AUTOSAR XML (schema 00050)
package /FCADT/ComponentTypes
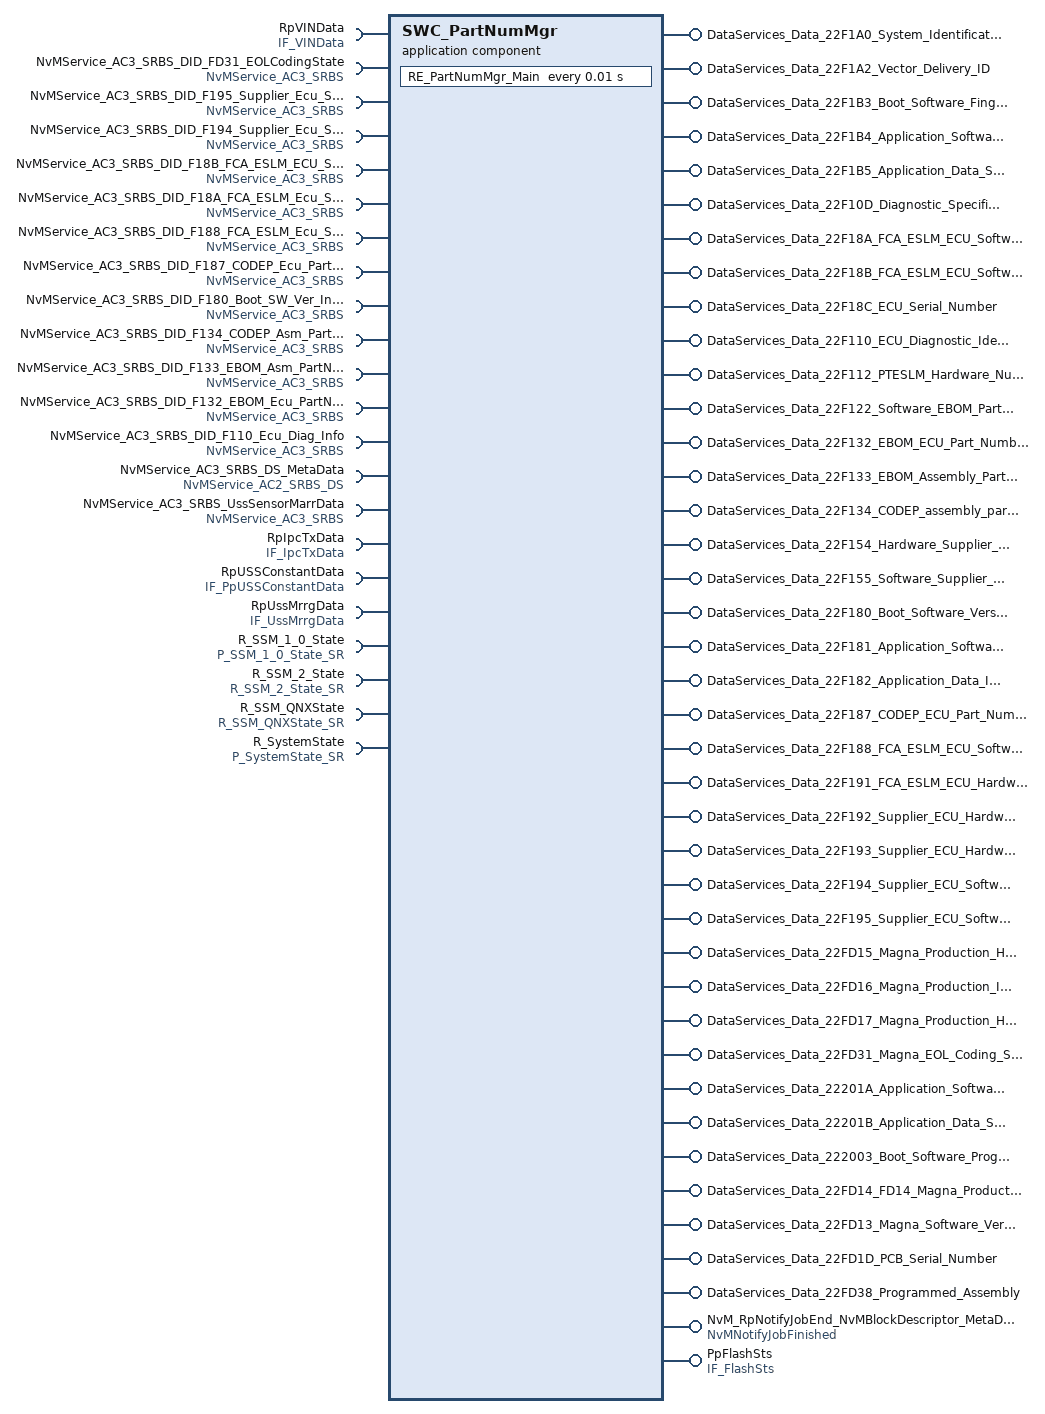
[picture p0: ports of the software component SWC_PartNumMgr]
  application sw component type SWC_PartNumMgr
    require port RpVINData: required-interface=IF_VINData
      required-com-specs:
        data-element=VINLockStatus, init-value=constant-reference=init_VINLockStatus
        data-element=VINOdoCounter, init-value=constant-reference=init_VINOdoCounter
        data-element=VINCurrentData, init-value=constant-reference=init_VINCurrentData
        data-element=VINOriginalData, init-value=constant-reference=init_VINOriginalData
    38 x provide port:
      DataServices_Data_22F1A0_System_Identification_Data: server-com-spec{operation=ReadData, queue-length=1}, provided-interface=DataServices_Data_22F1A0_System_Identification_Data
      DataServices_Data_22F1A2_Vector_Delivery_ID: server-com-spec{operation=ReadData, queue-length=1}, provided-interface=DataServices_Data_22F1A2_Vector_Delivery_ID
      DataServices_Data_22F1B3_Boot_Software_Fingerprint_Reading_Information: server-com-spec{operation=ReadData, queue-length=1}, provided-interface=DataServices_Data_22F1B3_Boot_Software_Fingerprint_Reading_Information
      DataServices_Data_22F1B4_Application_Software_Fingerprint_Reading_Information: server-com-spec{operation=ReadData, queue-length=1}, provided-interface=DataServices_Data_22F1B4_Application_Software_Fingerprint_Reading_Information
      DataServices_Data_22F1B5_Application_Data_Software_Fingerprint_Reading_Information: server-com-spec{operation=ReadData, queue-length=1}, provided-interface=DataServices_Data_22F1B5_Application_Data_Software_Fingerprint_Reading_Information
      DataServices_Data_22F10D_Diagnostic_Specification_Information: server-com-spec{operation=ReadData, queue-length=1}, provided-interface=DataServices_Data_22F10D_Diagnostic_Specification_Information
      DataServices_Data_22F18A_FCA_ESLM_ECU_Software_Calibration_Number: server-com-spec{operation=ReadData, queue-length=1}, provided-interface=DataServices_Data_22F18A_FCA_ESLM_ECU_Software_Calibration_Number
      DataServices_Data_22F18B_FCA_ESLM_ECU_Software_Application_Number: server-com-spec{operation=ReadData, queue-length=1}, provided-interface=DataServices_Data_22F18B_FCA_ESLM_ECU_Software_Application_Number
      DataServices_Data_22F18C_ECU_Serial_Number: server-com-spec{operation=ReadData, queue-length=1}, provided-interface=DataServices_Data_22F18C_ECU_Serial_Number
      DataServices_Data_22F110_ECU_Diagnostic_Identification: server-com-spec{operation=ReadData, queue-length=1}, provided-interface=DataServices_Data_22F110_ECU_Diagnostic_Identification
      DataServices_Data_22F112_PTESLM_Hardware_Number: server-com-spec{operation=ReadData, queue-length=1}, provided-interface=DataServices_Data_22F112_PTESLM_Hardware_Number
      DataServices_Data_22F122_Software_EBOM_Part_Number: server-com-spec{operation=ReadData, queue-length=1}, provided-interface=DataServices_Data_22F122_Software_EBOM_Part_Number
      DataServices_Data_22F132_EBOM_ECU_Part_Number: server-com-spec{operation=ReadData, queue-length=1}, provided-interface=DataServices_Data_22F132_EBOM_ECU_Part_Number
      DataServices_Data_22F133_EBOM_Assembly_Part_Number: server-com-spec{operation=ReadData, queue-length=1}, provided-interface=DataServices_Data_22F133_EBOM_Assembly_Part_Number
      DataServices_Data_22F134_CODEP_assembly_part_number: server-com-spec{operation=ReadData, queue-length=1}, provided-interface=DataServices_Data_22F134_CODEP_assembly_part_number
      DataServices_Data_22F154_Hardware_Supplier_Identification: server-com-spec{operation=ReadData, queue-length=1}, provided-interface=DataServices_Data_22F154_Hardware_Supplier_Identification
      DataServices_Data_22F155_Software_Supplier_Identification: server-com-spec{operation=ReadData, queue-length=1}, provided-interface=DataServices_Data_22F155_Software_Supplier_Identification
      DataServices_Data_22F180_Boot_Software_Version_Information: server-com-spec{operation=ReadData, queue-length=1}, provided-interface=DataServices_Data_22F180_Boot_Software_Version_Information
      DataServices_Data_22F181_Application_Software_Identification: server-com-spec{operation=ReadData, queue-length=1}, provided-interface=DataServices_Data_22F181_Application_Software_Identification
      DataServices_Data_22F182_Application_Data_Identification: server-com-spec{operation=ReadData, queue-length=1}, provided-interface=DataServices_Data_22F182_Application_Data_Identification
      DataServices_Data_22F187_CODEP_ECU_Part_Number: server-com-spec{operation=ReadData, queue-length=1}, provided-interface=DataServices_Data_22F187_CODEP_ECU_Part_Number
      DataServices_Data_22F188_FCA_ESLM_ECU_Software_Number: server-com-spec{operation=ReadData, queue-length=1}, provided-interface=DataServices_Data_22F188_FCA_ESLM_ECU_Software_Number
      DataServices_Data_22F191_FCA_ESLM_ECU_Hardware_Number: server-com-spec{operation=ReadData, queue-length=1}, provided-interface=DataServices_Data_22F191_FCA_ESLM_ECU_Hardware_Number
      DataServices_Data_22F192_Supplier_ECU_Hardware_Part_Number: server-com-spec{operation=ReadData, queue-length=1}, provided-interface=DataServices_Data_22F192_Supplier_ECU_Hardware_Part_Number
      DataServices_Data_22F193_Supplier_ECU_Hardware_Version_Number: server-com-spec{operation=ReadData, queue-length=1}, provided-interface=DataServices_Data_22F193_Supplier_ECU_Hardware_Version_Number
      DataServices_Data_22F194_Supplier_ECU_Software_Part_Number: server-com-spec{operation=ReadData, queue-length=1}, provided-interface=DataServices_Data_22F194_Supplier_ECU_Software_Part_Number
      DataServices_Data_22F195_Supplier_ECU_Software_Version_Number: server-com-spec{operation=ReadData, queue-length=1}, provided-interface=DataServices_Data_22F195_Supplier_ECU_Software_Version_Number
      DataServices_Data_22FD15_Magna_Production_HW_Number_Read: server-com-spec{operation=ReadData, queue-length=1}, provided-interface=DataServices_Data_22FD15_Magna_Production_HW_Number_Read
      DataServices_Data_22FD16_Magna_Production_ICT_Data_Read: server-com-spec{operation=ReadData, queue-length=1}, provided-interface=DataServices_Data_22FD16_Magna_Production_ICT_Data_Read
      DataServices_Data_22FD17_Magna_Production_HW_Version_information_Read: server-com-spec{operation=ReadData, queue-length=1}, provided-interface=DataServices_Data_22FD17_Magna_Production_HW_Version_information_Read
      DataServices_Data_22FD31_Magna_EOL_Coding_State_Read: provided-com-specs=[{operation=ReadData, queue-length=1}, {operation=WriteData, queue-length=1}], provided-interface=DataServices_Data_22FD31_Magna_EOL_Coding_State_Read
      DataServices_Data_22201A_Application_Software_Programming_Attempt_Counter: server-com-spec{operation=ReadData, queue-length=1}, provided-interface=DataServices_Data_22201A_Application_Software_Programming_Attempt_Counter
      DataServices_Data_22201B_Application_Data_Software_Programming_Attempt_Counter: server-com-spec{operation=ReadData, queue-length=1}, provided-interface=DataServices_Data_22201B_Application_Data_Software_Programming_Attempt_Counter
      DataServices_Data_222003_Boot_Software_Programming_Attempt_Counter: server-com-spec{operation=ReadData, queue-length=1}, provided-interface=DataServices_Data_222003_Boot_Software_Programming_Attempt_Counter
      DataServices_Data_22FD14_FD14_Magna_Production_Date_Read: server-com-spec{operation=ReadData, queue-length=1}, provided-interface=DataServices_Data_22FD14_FD14_Magna_Production_Date_Read
      DataServices_Data_22FD13_Magna_Software_Version: server-com-spec{operation=ReadData, queue-length=1}, provided-interface=DataServices_Data_22FD13_Magna_Software_Version
      DataServices_Data_22FD1D_PCB_Serial_Number: server-com-spec{operation=ReadData, queue-length=1}, provided-interface=DataServices_Data_22FD1D_PCB_Serial_Number
      DataServices_Data_22FD38_Programmed_Assembly: server-com-spec{operation=ReadData, queue-length=1}, provided-interface=DataServices_Data_22FD38_Programmed_Assembly
    13 x require port:
      NvMService_AC3_SRBS_DID_FD31_EOLCodingState: required-com-specs=[WriteBlock, SetRamBlockStatus, ReadBlock, InvalidateNvBlock, GetErrorStatus, EraseBlock], required-interface=NvMService_AC3_SRBS
      NvMService_AC3_SRBS_DID_F195_Supplier_Ecu_SW_VerNum: required-com-specs=[WriteBlock, SetRamBlockStatus, ReadBlock, InvalidateNvBlock, GetErrorStatus, EraseBlock], required-interface=NvMService_AC3_SRBS
      NvMService_AC3_SRBS_DID_F194_Supplier_Ecu_SW_PartNum: required-com-specs=[WriteBlock, SetRamBlockStatus, ReadBlock, InvalidateNvBlock, GetErrorStatus, EraseBlock], required-interface=NvMService_AC3_SRBS
      NvMService_AC3_SRBS_DID_F18B_FCA_ESLM_ECU_SW_App_Num: required-com-specs=[WriteBlock, SetRamBlockStatus, ReadBlock, InvalidateNvBlock, GetErrorStatus, EraseBlock], required-interface=NvMService_AC3_SRBS
      NvMService_AC3_SRBS_DID_F18A_FCA_ESLM_Ecu_SW_Cal_Num: required-com-specs=[WriteBlock, SetRamBlockStatus, ReadBlock, InvalidateNvBlock, GetErrorStatus, EraseBlock], required-interface=NvMService_AC3_SRBS
      NvMService_AC3_SRBS_DID_F188_FCA_ESLM_Ecu_SW_Num: required-com-specs=[WriteBlock, SetRamBlockStatus, ReadBlock, InvalidateNvBlock, GetErrorStatus, EraseBlock], required-interface=NvMService_AC3_SRBS
      NvMService_AC3_SRBS_DID_F187_CODEP_Ecu_PartNum: required-com-specs=[WriteBlock, SetRamBlockStatus, ReadBlock, InvalidateNvBlock, GetErrorStatus, EraseBlock], required-interface=NvMService_AC3_SRBS
      NvMService_AC3_SRBS_DID_F180_Boot_SW_Ver_Info: required-com-specs=[WriteBlock, SetRamBlockStatus, ReadBlock, InvalidateNvBlock, GetErrorStatus, EraseBlock], required-interface=NvMService_AC3_SRBS
      NvMService_AC3_SRBS_DID_F134_CODEP_Asm_PartNum: required-com-specs=[WriteBlock, SetRamBlockStatus, ReadBlock, InvalidateNvBlock, GetErrorStatus, EraseBlock], required-interface=NvMService_AC3_SRBS
      NvMService_AC3_SRBS_DID_F133_EBOM_Asm_PartNum: required-com-specs=[WriteBlock, SetRamBlockStatus, ReadBlock, InvalidateNvBlock, GetErrorStatus, EraseBlock], required-interface=NvMService_AC3_SRBS
      NvMService_AC3_SRBS_DID_F132_EBOM_Ecu_PartNum: required-com-specs=[WriteBlock, SetRamBlockStatus, ReadBlock, InvalidateNvBlock, GetErrorStatus, EraseBlock], required-interface=NvMService_AC3_SRBS
      NvMService_AC3_SRBS_DID_F110_Ecu_Diag_Info: required-com-specs=[WriteBlock, SetRamBlockStatus, ReadBlock, InvalidateNvBlock, GetErrorStatus, EraseBlock], required-interface=NvMService_AC3_SRBS
      NvMService_AC3_SRBS_DS_MetaData: required-com-specs=[WriteBlock, SetRamBlockStatus, SetDataIndex, ReadBlock, GetErrorStatus, GetDataIndex], required-interface=NvMService_AC2_SRBS_DS
    provide port NvM_RpNotifyJobEnd_NvMBlockDescriptor_MetaData: server-com-spec{operation=JobFinished, queue-length=1}, provided-interface=NvMNotifyJobFinished
    7 x require port:
      NvMService_AC3_SRBS_UssSensorMarrData: required-com-specs=[WriteBlock, SetRamBlockStatus, ReadBlock, InvalidateNvBlock, GetErrorStatus, EraseBlock], required-interface=NvMService_AC3_SRBS
      RpIpcTxData: client-com-spec=IPC_Write_v, required-interface=IF_IpcTxData
      RpUSSConstantData: nonqueued-receiver-com-spec{data-element=US_S_USSConstantData_t, filter=data-filter-type=ALWAYS}, required-interface=IF_PpUSSConstantData
      RpUssMrrgData: nonqueued-receiver-com-spec{data-element=US_S_MarriageSensorIDs_t, filter=data-filter-type=ALWAYS, init-value=fields=[bValid:0, uMarriageStatus:0, uSavedSensorIDs:12 x 0]}, required-interface=IF_UssMrrgData
      R_SSM_1_0_State: nonqueued-receiver-com-spec{data-element=State_1_0, init-value=fields=[CoreStatus:0, LocalAppStatus:20 x 0]}, required-interface=P_SSM_1_0_State_SR
      R_SSM_2_State: required-interface=R_SSM_2_State_SR
        required-com-specs:
          data-element=State_2_0, init-value=fields=[CoreStatus:0, LocalAppStatus:20 x 0]
          data-element=State_2_1, filter=data-filter-type=ALWAYS, init-value=fields=[CoreStatus:0, LocalAppStatus:20 x 0]
      R_SSM_QNXState: nonqueued-receiver-com-spec{data-element=State_QNX, init-value=fields=[CoreStatus:0, LocalAppStatus:20 x 0]}, required-interface=R_SSM_QNXState_SR
    provide port PpFlashSts: nonqueued-sender-com-spec{data-element=v_FlashSts_u16, init-value=0}, provided-interface=IF_FlashSts
    require port R_SystemState: nonqueued-receiver-com-spec=data-element=SystemState, required-interface=P_SystemState_SR
    behavior SWC_PartNumMgr_InternalBehavior: handle-termination-and-restart=NO-SUPPORT
      ar-typed-per-instance-memorys:
        13 x data, all with sw-calibration-access=READ-ONLY:
          DID_FD31_EOLCodingState_MirrorBlock: type=Dcm_Data4ByteType
          DID_F195_Supplier_Ecu_SW_VerNum_MirrorBlock: type=Dcm_Data2ByteType
          DID_F194_Supplier_Ecu_SW_PartNum_MirrorBlock: type=Dcm_Data11ByteType
          DID_F18B_FCA_ESLM_ECU_SW_App_Num_MirrorBlock: type=Dcm_Data10ByteType
          DID_F18A_FCA_ESLM_Ecu_SW_Cal_Num_MirrorBlock: type=Dcm_Data10ByteType
          DID_F188_FCA_ESLM_Ecu_SW_Num_MirrorBlock: type=Dcm_Data11ByteType
          DID_F187_CODEP_Ecu_PartNum_MirrorBlock: type=Dcm_Data11ByteType
          DID_F180_Boot_SW_Ver_Info_MirrorBlock: type=Dcm_Data13ByteType
          DID_F134_CODEP_Asm_PartNum_MirrorBlock: type=Dcm_Data11ByteType
          DID_F133_EBOM_Asm_PartNum_MirrorBlock: type=Dcm_Data10ByteType
          DID_F132_EBOM_Ecu_PartNum_MirrorBlock: type=Dcm_Data10ByteType
          DID_F110_Ecu_Diag_Info_MirrorBlock: type=DID_F110_Pin_Arr
          UssSensorMarrData_MirrorBlock: type=US_S_MarriageSensorIDs_t
      init event InitEvent: start-on-event=RE_PartNumMgr_Init
      timing event TMT_RE_PartNumMgr_Main: start-on-event=RE_PartNumMgr_Main, period=0.01
      40 x operation invoked event:
        OIT_DataServices_Data_222003_Boot_Software_Programming_Attempt_Counter_ReadData_DataServices_Data_222003_Boot_Software_P7618A5A4: start-on-event=DataServices_Data_222003_Boot_Software_Programming_Attempt_Counter_ReadData, operation=DataServices_Data_222003_Boot_Software_Programming_Attempt_Counter.ReadData
        OIT_DataServices_Data_22F180_Boot_Software_Version_Information_ReadData_DataServices_Data_22F180_Boot_Software_Version_IFD2EFA80: start-on-event=DataServices_Data_22F180_Boot_Software_Version_Information_ReadData, operation=DataServices_Data_22F180_Boot_Software_Version_Information.ReadData
        OIT_DataServices_Data_22F18A_FCA_ESLM_ECU_Software_Calibration_Number_ReadData_DataServices_Data_22F18A_FCA_ESLM_ECU_SofDF68DFA8: start-on-event=DataServices_Data_22F18A_FCA_ESLM_ECU_Software_Calibration_Number_ReadData, operation=DataServices_Data_22F18A_FCA_ESLM_ECU_Software_Calibration_Number.ReadData
        OIT_DataServices_Data_22FD16_Magna_Production_ICT_Data_Read_ReadData_DataServices_Data_22FD16_Magna_Production_ICT_Data_1B05D7E7: start-on-event=DataServices_Data_22FD16_Magna_Production_ICT_Data_Read_ReadData, operation=DataServices_Data_22FD16_Magna_Production_ICT_Data_Read.ReadData
        OIT_DataServices_Data_22F188_FCA_ESLM_ECU_Software_Number_ReadData_DataServices_Data_22F188_FCA_ESLM_ECU_Software_Number457EFB64: start-on-event=DataServices_Data_22F188_FCA_ESLM_ECU_Software_Number_ReadData, operation=DataServices_Data_22F188_FCA_ESLM_ECU_Software_Number.ReadData
        OIT_DataServices_Data_22F182_Application_Data_Identification_ReadData_DataServices_Data_22F182_Application_Data_IdentifiB7E15006: start-on-event=DataServices_Data_22F182_Application_Data_Identification_ReadData, operation=DataServices_Data_22F182_Application_Data_Identification.ReadData
        OIT_DataServices_Data_22F192_Supplier_ECU_Hardware_Part_Number_ReadData_DataServices_Data_22F192_Supplier_ECU_Hardware_P8807FD4D: start-on-event=DataServices_Data_22F192_Supplier_ECU_Hardware_Part_Number_ReadData, operation=DataServices_Data_22F192_Supplier_ECU_Hardware_Part_Number.ReadData
        OIT_DataServices_Data_22F10D_Diagnostic_Specification_Information_ReadData_DataServices_Data_22F10D_Diagnostic_Specifica91CF8A26: start-on-event=DataServices_Data_22F10D_Diagnostic_Specification_Information_ReadData, operation=DataServices_Data_22F10D_Diagnostic_Specification_Information.ReadData
        OIT_DataServices_Data_22FD17_Magna_Production_HW_Version_information_Read_ReadData_DataServices_Data_22FD17_Magna_Produc06BFFE9B: start-on-event=DataServices_Data_22FD17_Magna_Production_HW_Version_information_Read_ReadData, operation=DataServices_Data_22FD17_Magna_Production_HW_Version_information_Read.ReadData
        OIT_DataServices_Data_22F191_FCA_ESLM_ECU_Hardware_Number_ReadData_DataServices_Data_22F191_FCA_ESLM_ECU_Hardware_Number5EEDE70D: start-on-event=DataServices_Data_22F191_FCA_ESLM_ECU_Hardware_Number_ReadData, operation=DataServices_Data_22F191_FCA_ESLM_ECU_Hardware_Number.ReadData
        OIT_DataServices_Data_22F1B5_Application_Data_Software_Fingerprint_Reading_Information_ReadData_DataServices_Data_22F1B51DE0B2F4: start-on-event=DataServices_Data_22F1B5_Application_Data_Software_Fingerprint_Reading_Information_ReadData, operation=DataServices_Data_22F1B5_Application_Data_Software_Fingerprint_Reading_Information.ReadData
        OIT_DataServices_Data_22FD15_Magna_Production_HW_Number_Read_ReadData_DataServices_Data_22FD15_Magna_Production_HW_Numbe6743EEE1: start-on-event=DataServices_Data_22FD15_Magna_Production_HW_Number_Read_ReadData, operation=DataServices_Data_22FD15_Magna_Production_HW_Number_Read.ReadData
        OIT_DataServices_Data_22F154_Hardware_Supplier_Identification_ReadData_DataServices_Data_22F154_Hardware_Supplier_Identi565FF852: start-on-event=DataServices_Data_22F154_Hardware_Supplier_Identification_ReadData, operation=DataServices_Data_22F154_Hardware_Supplier_Identification.ReadData
        OIT_DataServices_Data_22F132_EBOM_ECU_Part_Number_ReadData_DataServices_Data_22F132_EBOM_ECU_Part_Number_ReadData: start-on-event=DataServices_Data_22F132_EBOM_ECU_Part_Number_ReadData, operation=DataServices_Data_22F132_EBOM_ECU_Part_Number.ReadData
        OIT_DataServices_Data_22F110_ECU_Diagnostic_Identification_ReadData_DataServices_Data_22F110_ECU_Diagnostic_IdentificatiE46CBB4A: start-on-event=DataServices_Data_22F110_ECU_Diagnostic_Identification_ReadData, operation=DataServices_Data_22F110_ECU_Diagnostic_Identification.ReadData
        OIT_DataServices_Data_22F133_EBOM_Assembly_Part_Number_ReadData_DataServices_Data_22F133_EBOM_Assembly_Part_Number_ReadData: start-on-event=DataServices_Data_22F133_EBOM_Assembly_Part_Number_ReadData, operation=DataServices_Data_22F133_EBOM_Assembly_Part_Number.ReadData
        OIT_DataServices_Data_22F134_CODEP_assembly_part_number_ReadData_DataServices_Data_22F134_CODEP_assembly_part_number_ReadData: start-on-event=DataServices_Data_22F134_CODEP_assembly_part_number_ReadData, operation=DataServices_Data_22F134_CODEP_assembly_part_number.ReadData
        OIT_DataServices_Data_22F112_PTESLM_Hardware_Number_ReadData_DataServices_Data_22F112_PTESLM_Hardware_Number_ReadData: start-on-event=DataServices_Data_22F112_PTESLM_Hardware_Number_ReadData, operation=DataServices_Data_22F112_PTESLM_Hardware_Number.ReadData
        OIT_DataServices_Data_22201A_Application_Software_Programming_Attempt_Counter_ReadData_DataServices_Data_22201A_ApplicatCDDECFD6: start-on-event=DataServices_Data_22201A_Application_Software_Programming_Attempt_Counter_ReadData, operation=DataServices_Data_22201A_Application_Software_Programming_Attempt_Counter.ReadData
        OIT_DataServices_Data_22F194_Supplier_ECU_Software_Part_Number_ReadData_DataServices_Data_22F194_Supplier_ECU_Software_PF5FA3120: start-on-event=DataServices_Data_22F194_Supplier_ECU_Software_Part_Number_ReadData, operation=DataServices_Data_22F194_Supplier_ECU_Software_Part_Number.ReadData
        OIT_DataServices_Data_22F181_Application_Software_Identification_ReadData_DataServices_Data_22F181_Application_Software_D66047AC: start-on-event=DataServices_Data_22F181_Application_Software_Identification_ReadData, operation=DataServices_Data_22F181_Application_Software_Identification.ReadData
        OIT_DataServices_Data_22F195_Supplier_ECU_Software_Version_Number_ReadData_DataServices_Data_22F195_Supplier_ECU_SoftwarD5BB4A4E: start-on-event=DataServices_Data_22F195_Supplier_ECU_Software_Version_Number_ReadData, operation=DataServices_Data_22F195_Supplier_ECU_Software_Version_Number.ReadData
        OIT_DataServices_Data_22F18C_ECU_Serial_Number_ReadData_DataServices_Data_22F18C_ECU_Serial_Number_ReadData: start-on-event=DataServices_Data_22F18C_ECU_Serial_Number_ReadData, operation=DataServices_Data_22F18C_ECU_Serial_Number.ReadData
        OIT_DataServices_Data_22F193_Supplier_ECU_Hardware_Version_Number_ReadData_DataServices_Data_22F193_Supplier_ECU_Hardwar33F2C41C: start-on-event=DataServices_Data_22F193_Supplier_ECU_Hardware_Version_Number_ReadData, operation=DataServices_Data_22F193_Supplier_ECU_Hardware_Version_Number.ReadData
        OIT_DataServices_Data_22F155_Software_Supplier_Identification_ReadData_DataServices_Data_22F155_Software_Supplier_Identi5611B37E: start-on-event=DataServices_Data_22F155_Software_Supplier_Identification_ReadData, operation=DataServices_Data_22F155_Software_Supplier_Identification.ReadData
        OIT_DataServices_Data_22F1A0_System_Identification_Data_ReadData_DataServices_Data_22F1A0_System_Identification_Data_ReadData: start-on-event=DataServices_Data_22F1A0_System_Identification_Data_ReadData, operation=DataServices_Data_22F1A0_System_Identification_Data.ReadData
        OIT_DataServices_Data_22F1B3_Boot_Software_Fingerprint_Reading_Information_ReadData_DataServices_Data_22F1B3_Boot_Softwa5F5B6A24: start-on-event=DataServices_Data_22F1B3_Boot_Software_Fingerprint_Reading_Information_ReadData, operation=DataServices_Data_22F1B3_Boot_Software_Fingerprint_Reading_Information.ReadData
        OIT_DataServices_Data_22F18B_FCA_ESLM_ECU_Software_Application_Number_ReadData_DataServices_Data_22F18B_FCA_ESLM_ECU_Sof869D5A40: start-on-event=DataServices_Data_22F18B_FCA_ESLM_ECU_Software_Application_Number_ReadData, operation=DataServices_Data_22F18B_FCA_ESLM_ECU_Software_Application_Number.ReadData
        OIT_DataServices_Data_22F187_CODEP_ECU_Part_Number_ReadData_DataServices_Data_22F187_CODEP_ECU_Part_Number_ReadData: start-on-event=DataServices_Data_22F187_CODEP_ECU_Part_Number_ReadData, operation=DataServices_Data_22F187_CODEP_ECU_Part_Number.ReadData
        OIT_DataServices_Data_22201B_Application_Data_Software_Programming_Attempt_Counter_ReadData_DataServices_Data_22201B_App20424928: start-on-event=DataServices_Data_22201B_Application_Data_Software_Programming_Attempt_Counter_ReadData, operation=DataServices_Data_22201B_Application_Data_Software_Programming_Attempt_Counter.ReadData
        OIT_DataServices_Data_22F1B4_Application_Software_Fingerprint_Reading_Information_ReadData_DataServices_Data_22F1B4_Appl1F41231D: start-on-event=DataServices_Data_22F1B4_Application_Software_Fingerprint_Reading_Information_ReadData, operation=DataServices_Data_22F1B4_Application_Software_Fingerprint_Reading_Information.ReadData
        OIT_DataServices_Data_22FD31_Magna_EOL_Coding_State_Read_WriteData_DataServices_Data_22FD31_Magna_EOL_Coding_State_Read_6E34A382: start-on-event=DataServices_Data_22FD31_Magna_EOL_Coding_State_Read_WriteData, operation=DataServices_Data_22FD31_Magna_EOL_Coding_State_Read.WriteData
        OIT_DataServices_Data_22FD31_Magna_EOL_Coding_State_Read_ReadData_DataServices_Data_22FD31_Magna_EOL_Coding_State_Read_ReadData: start-on-event=DataServices_Data_22FD31_Magna_EOL_Coding_State_Read_ReadData, operation=DataServices_Data_22FD31_Magna_EOL_Coding_State_Read.ReadData
        OIT_DataServices_Data_22F122_Software_EBOM_Part_Number_ReadData_DataServices_Data_22F122_Software_EBOM_Part_Number_ReadData: start-on-event=DataServices_Data_22F122_Software_EBOM_Part_Number_ReadData, operation=DataServices_Data_22F122_Software_EBOM_Part_Number.ReadData
        OIT_DataServices_Data_22F1A2_Vector_Delivery_ID_ReadData_DataServices_Data_22F1A2_Vector_Delivery_ID_ReadData: start-on-event=DataServices_Data_22F1A2_Vector_Delivery_ID_ReadData, operation=DataServices_Data_22F1A2_Vector_Delivery_ID.ReadData
        OIT_DataServices_Data_22FD13_Magna_Software_Version_ReadData_1_DataServices_Data_22FD13_Magna_Software_Version_ReadData: start-on-event=DataServices_Data_22FD13_Magna_Software_Version_ReadData, operation=DataServices_Data_22FD13_Magna_Software_Version.ReadData
        OIT_DataServices_Data_22FD14_FD14_Magna_Production_Date_Read_ReadData_1_DataServices_Data_22FD14_FD14_Magna_Production_DC024ADC0: start-on-event=DataServices_Data_22FD14_FD14_Magna_Production_Date_Read_ReadData, operation=DataServices_Data_22FD14_FD14_Magna_Production_Date_Read.ReadData
        OIT_DataServices_Data_22FD38_Programmed_Assembly_ReadData_1_DataServices_Data_22FD38_Programmed_Assembly_ReadData: start-on-event=DataServices_Data_22FD38_Programmed_Assembly_ReadData, operation=DataServices_Data_22FD38_Programmed_Assembly.ReadData
        OIT_DataServices_Data_22FD1D_PCB_Serial_Number_ReadData_1_DataServices_Data_22FD1D_PCB_Serial_Number_ReadData: start-on-event=DataServices_Data_22FD1D_PCB_Serial_Number_ReadData, operation=DataServices_Data_22FD1D_PCB_Serial_Number.ReadData
        OIT_RE_NvM_RpNotifyJobEnd_NvMBlockDescriptor_MetaData_JobFinished_NvM_RpNotifyJobEnd_NvMBlockDescriptor_MetaData_JobFinished: start-on-event=RE_NvM_RpNotifyJobEnd_NvMBlockDescriptor_MetaData_JobFinished, operation=NvM_RpNotifyJobEnd_NvMBlockDescriptor_MetaData.JobFinished
      per-instance-parameters:
        13 x parameter data prototype, all with sw-calibration-access=READ-WRITE:
          DID_FD31_EOLCodingState_DefaultValue: type=Dcm_Data4ByteType, init-value=[0, 0, 0, 0]
          DID_F195_Supplier_Ecu_SW_VerNum_DefaultValue: type=Dcm_Data2ByteType, init-value=[0, 0]
          DID_F194_Supplier_Ecu_SW_PartNum_DefaultValue: type=Dcm_Data11ByteType, init-value=11 x 0
          DID_F18B_FCA_ESLM_ECU_SW_App_Num_DefaultValue: type=Dcm_Data10ByteType, init-value=10 x 0
          DID_F18A_FCA_ESLM_Ecu_SW_Cal_Num_DefaultValue: type=Dcm_Data10ByteType, init-value=10 x 0
          DID_F188_FCA_ESLM_Ecu_SW_Num_DefaultValue: type=Dcm_Data11ByteType, init-value=11 x 0
          DID_F187_CODEP_Ecu_PartNum_DefaultValue: type=Dcm_Data11ByteType, init-value=11 x 0
          DID_F180_Boot_SW_Ver_Info_DefaultValue: type=Dcm_Data13ByteType, init-value=13 x 0
          DID_F134_CODEP_Asm_PartNum_DefaultValue: type=Dcm_Data11ByteType, init-value=11 x 0
          DID_F133_EBOM_Asm_PartNum_DefaultValue: type=Dcm_Data10ByteType, init-value=10 x 0
          DID_F132_EBOM_Ecu_PartNum_DefaultValue: type=Dcm_Data10ByteType, init-value=10 x 0
          DID_F110_Ecu_Diag_Info_DefaultValue: type=DID_F110_Pin_Arr, init-value=6 x 0
          UssSensorMarrData_DefaultValue: type=US_S_MarriageSensorIDs_t, init-value=fields=[bValid:0, uMarriageStatus:0, uSavedSensorIDs:12 x 0]
      port-api-options:
        enable-take-address=false, error-handling=NO-TRANSFORMER-ERROR-HANDLING, indirect-api=false, port=RpVINData
        enable-take-address=false, error-handling=NO-TRANSFORMER-ERROR-HANDLING, indirect-api=false, port=DataServices_Data_222003_Boot_Software_Programming_Attempt_Counter
        enable-take-address=false, error-handling=NO-TRANSFORMER-ERROR-HANDLING, indirect-api=false, port=DataServices_Data_22201A_Application_Software_Programming_Attempt_Counter
        enable-take-address=false, error-handling=NO-TRANSFORMER-ERROR-HANDLING, indirect-api=false, port=DataServices_Data_22201B_Application_Data_Software_Programming_Attempt_Counter
        enable-take-address=false, error-handling=NO-TRANSFORMER-ERROR-HANDLING, indirect-api=false, port=DataServices_Data_22F10D_Diagnostic_Specification_Information
        enable-take-address=false, error-handling=NO-TRANSFORMER-ERROR-HANDLING, indirect-api=false, port=DataServices_Data_22F110_ECU_Diagnostic_Identification
        enable-take-address=false, error-handling=NO-TRANSFORMER-ERROR-HANDLING, indirect-api=false, port=DataServices_Data_22F112_PTESLM_Hardware_Number
        enable-take-address=false, error-handling=NO-TRANSFORMER-ERROR-HANDLING, indirect-api=false, port=DataServices_Data_22F122_Software_EBOM_Part_Number
        enable-take-address=false, error-handling=NO-TRANSFORMER-ERROR-HANDLING, indirect-api=false, port=DataServices_Data_22F132_EBOM_ECU_Part_Number
        enable-take-address=false, error-handling=NO-TRANSFORMER-ERROR-HANDLING, indirect-api=false, port=DataServices_Data_22F133_EBOM_Assembly_Part_Number
        enable-take-address=false, error-handling=NO-TRANSFORMER-ERROR-HANDLING, indirect-api=false, port=DataServices_Data_22F134_CODEP_assembly_part_number
        enable-take-address=false, error-handling=NO-TRANSFORMER-ERROR-HANDLING, indirect-api=false, port=DataServices_Data_22F154_Hardware_Supplier_Identification
        enable-take-address=false, error-handling=NO-TRANSFORMER-ERROR-HANDLING, indirect-api=false, port=DataServices_Data_22F155_Software_Supplier_Identification
        enable-take-address=false, error-handling=NO-TRANSFORMER-ERROR-HANDLING, indirect-api=false, port=DataServices_Data_22F180_Boot_Software_Version_Information
        enable-take-address=false, error-handling=NO-TRANSFORMER-ERROR-HANDLING, indirect-api=false, port=DataServices_Data_22F181_Application_Software_Identification
        enable-take-address=false, error-handling=NO-TRANSFORMER-ERROR-HANDLING, indirect-api=false, port=DataServices_Data_22F182_Application_Data_Identification
        enable-take-address=false, error-handling=NO-TRANSFORMER-ERROR-HANDLING, indirect-api=false, port=DataServices_Data_22F187_CODEP_ECU_Part_Number
        enable-take-address=false, error-handling=NO-TRANSFORMER-ERROR-HANDLING, indirect-api=false, port=DataServices_Data_22F188_FCA_ESLM_ECU_Software_Number
        enable-take-address=false, error-handling=NO-TRANSFORMER-ERROR-HANDLING, indirect-api=false, port=DataServices_Data_22F18A_FCA_ESLM_ECU_Software_Calibration_Number
        enable-take-address=false, error-handling=NO-TRANSFORMER-ERROR-HANDLING, indirect-api=false, port=DataServices_Data_22F18B_FCA_ESLM_ECU_Software_Application_Number
        enable-take-address=false, error-handling=NO-TRANSFORMER-ERROR-HANDLING, indirect-api=false, port=DataServices_Data_22F18C_ECU_Serial_Number
        enable-take-address=false, error-handling=NO-TRANSFORMER-ERROR-HANDLING, indirect-api=false, port=DataServices_Data_22F191_FCA_ESLM_ECU_Hardware_Number
        enable-take-address=false, error-handling=NO-TRANSFORMER-ERROR-HANDLING, indirect-api=false, port=DataServices_Data_22F192_Supplier_ECU_Hardware_Part_Number
        enable-take-address=false, error-handling=NO-TRANSFORMER-ERROR-HANDLING, indirect-api=false, port=DataServices_Data_22F193_Supplier_ECU_Hardware_Version_Number
        enable-take-address=false, error-handling=NO-TRANSFORMER-ERROR-HANDLING, indirect-api=false, port=DataServices_Data_22F194_Supplier_ECU_Software_Part_Number
        enable-take-address=false, error-handling=NO-TRANSFORMER-ERROR-HANDLING, indirect-api=false, port=DataServices_Data_22F195_Supplier_ECU_Software_Version_Number
        enable-take-address=false, error-handling=NO-TRANSFORMER-ERROR-HANDLING, indirect-api=false, port=DataServices_Data_22F1A0_System_Identification_Data
        enable-take-address=false, error-handling=NO-TRANSFORMER-ERROR-HANDLING, indirect-api=false, port=DataServices_Data_22F1A2_Vector_Delivery_ID
        enable-take-address=false, error-handling=NO-TRANSFORMER-ERROR-HANDLING, indirect-api=false, port=DataServices_Data_22F1B3_Boot_Software_Fingerprint_Reading_Information
        enable-take-address=false, error-handling=NO-TRANSFORMER-ERROR-HANDLING, indirect-api=false, port=DataServices_Data_22F1B4_Application_Software_Fingerprint_Reading_Information
        enable-take-address=false, error-handling=NO-TRANSFORMER-ERROR-HANDLING, indirect-api=false, port=DataServices_Data_22F1B5_Application_Data_Software_Fingerprint_Reading_Information
        enable-take-address=false, error-handling=NO-TRANSFORMER-ERROR-HANDLING, indirect-api=false, port=DataServices_Data_22FD15_Magna_Production_HW_Number_Read
        enable-take-address=false, error-handling=NO-TRANSFORMER-ERROR-HANDLING, indirect-api=false, port=DataServices_Data_22FD16_Magna_Production_ICT_Data_Read
        enable-take-address=false, error-handling=NO-TRANSFORMER-ERROR-HANDLING, indirect-api=false, port=DataServices_Data_22FD17_Magna_Production_HW_Version_information_Read
        enable-take-address=false, error-handling=NO-TRANSFORMER-ERROR-HANDLING, indirect-api=false, port=DataServices_Data_22FD31_Magna_EOL_Coding_State_Read
      42 x runnable:
        RE_PartNumMgr_Init
          sync call SC_NvMService_AC3_SRBS_DS_MetaData_ReadBlock: operation=NvMService_AC3_SRBS_DS_MetaData.ReadBlock
          sync call SC_NvMService_AC3_SRBS_DS_MetaData_SetDataIndex: operation=NvMService_AC3_SRBS_DS_MetaData.SetDataIndex
        RE_PartNumMgr_Main
          data-receive-point-by-arguments:
            11 x access:
              REC_RpVINData_VINCurrentData: accessed-variable=RpVINData.VINCurrentData
              REC_RpVINData_VINLockStatus: accessed-variable=RpVINData.VINLockStatus
              REC_RpVINData_VINOdoCounter: accessed-variable=RpVINData.VINOdoCounter
              REC_RpVINData_VINOriginalData: accessed-variable=RpVINData.VINOriginalData
              REC_RpUSSConstantData_US_S_USSConstantData_t: accessed-variable=RpUSSConstantData.US_S_USSConstantData_t
              REC_RpUssMrrgData_US_S_MarriageSensorIDs_t: accessed-variable=RpUssMrrgData.US_S_MarriageSensorIDs_t
              REC_R_SSM_1_0_State_State_1_0: accessed-variable=R_SSM_1_0_State.State_1_0
              REC_R_SSM_2_State_State_2_0: accessed-variable=R_SSM_2_State.State_2_0
              REC_R_SSM_2_State_State_2_1: accessed-variable=R_SSM_2_State.State_2_1
              REC_R_SSM_QNXState_State_QNX: accessed-variable=R_SSM_QNXState.State_QNX
              REC_R_SystemState_SystemState: accessed-variable=R_SystemState.SystemState
          data-send-points:
            access SEND_PpFlashSts_v_FlashSts_u16: accessed-variable=PpFlashSts.v_FlashSts_u16
          4 x sync call:
            SC_NvMService_AC3_SRBS_DID_FD31_EOLCodingState_SetRamBlockStatus: operation=NvMService_AC3_SRBS_DID_FD31_EOLCodingState.SetRamBlockStatus
            SC_NvMService_AC3_SRBS_UssSensorMarrData_SetRamBlockStatus: operation=NvMService_AC3_SRBS_UssSensorMarrData.SetRamBlockStatus
            SC_NvMService_AC3_SRBS_UssSensorMarrData_WriteBlock: operation=NvMService_AC3_SRBS_UssSensorMarrData.WriteBlock
            SC_RpIpcTxData_IPC_Write_v: operation=RpIpcTxData.IPC_Write_v
        DataServices_Data_222003_Boot_Software_Programming_Attempt_Counter_ReadData
        DataServices_Data_22F180_Boot_Software_Version_Information_ReadData
        DataServices_Data_22F18A_FCA_ESLM_ECU_Software_Calibration_Number_ReadData
        DataServices_Data_22FD16_Magna_Production_ICT_Data_Read_ReadData
        DataServices_Data_22F188_FCA_ESLM_ECU_Software_Number_ReadData
        DataServices_Data_22F182_Application_Data_Identification_ReadData
        DataServices_Data_22F192_Supplier_ECU_Hardware_Part_Number_ReadData
        DataServices_Data_22F10D_Diagnostic_Specification_Information_ReadData
        DataServices_Data_22FD17_Magna_Production_HW_Version_information_Read_ReadData
        DataServices_Data_22F191_FCA_ESLM_ECU_Hardware_Number_ReadData
        DataServices_Data_22F1B5_Application_Data_Software_Fingerprint_Reading_Information_ReadData
        DataServices_Data_22FD15_Magna_Production_HW_Number_Read_ReadData
        DataServices_Data_22F154_Hardware_Supplier_Identification_ReadData
        DataServices_Data_22F132_EBOM_ECU_Part_Number_ReadData
        DataServices_Data_22F110_ECU_Diagnostic_Identification_ReadData
        DataServices_Data_22F133_EBOM_Assembly_Part_Number_ReadData
        DataServices_Data_22F134_CODEP_assembly_part_number_ReadData
        DataServices_Data_22F112_PTESLM_Hardware_Number_ReadData
        DataServices_Data_22201A_Application_Software_Programming_Attempt_Counter_ReadData
        DataServices_Data_22F194_Supplier_ECU_Software_Part_Number_ReadData
        DataServices_Data_22F181_Application_Software_Identification_ReadData
        DataServices_Data_22F195_Supplier_ECU_Software_Version_Number_ReadData
        DataServices_Data_22F18C_ECU_Serial_Number_ReadData
        DataServices_Data_22F193_Supplier_ECU_Hardware_Version_Number_ReadData
        DataServices_Data_22F155_Software_Supplier_Identification_ReadData
        DataServices_Data_22F1A0_System_Identification_Data_ReadData
        DataServices_Data_22F1B3_Boot_Software_Fingerprint_Reading_Information_ReadData
        DataServices_Data_22F18B_FCA_ESLM_ECU_Software_Application_Number_ReadData
        DataServices_Data_22F187_CODEP_ECU_Part_Number_ReadData
        DataServices_Data_22201B_Application_Data_Software_Programming_Attempt_Counter_ReadData
        DataServices_Data_22F1B4_Application_Software_Fingerprint_Reading_Information_ReadData
        DataServices_Data_22FD31_Magna_EOL_Coding_State_Read_WriteData
        DataServices_Data_22FD31_Magna_EOL_Coding_State_Read_ReadData
        DataServices_Data_22F122_Software_EBOM_Part_Number_ReadData
        DataServices_Data_22F1A2_Vector_Delivery_ID_ReadData
        DataServices_Data_22FD13_Magna_Software_Version_ReadData
        DataServices_Data_22FD14_FD14_Magna_Production_Date_Read_ReadData
        DataServices_Data_22FD38_Programmed_Assembly_ReadData
        DataServices_Data_22FD1D_PCB_Serial_Number_ReadData
        RE_NvM_RpNotifyJobEnd_NvMBlockDescriptor_MetaData_JobFinished
      13 x swc service dependency, all with category=SERVICE:
        DID_FD31_EOLCodingState: assigned-ports=role-based-port-assignment={port-prototype=NvMService_AC3_SRBS_DID_FD31_EOLCodingState, role=NvMService_AC3_SRBS}
          assigned-datas:
            role=ramBlock, used-data-element=DID_FD31_EOLCodingState_MirrorBlock
            role=defaultValue, used-parameter-element=DID_FD31_EOLCodingState_DefaultValue
          service-needs:
            nv block needs DID_FD31_EOLCodingState: n-data-sets=1, ram-block-status-control=API, reliability=NO-PROTECTION, restore-at-start=true, store-at-shutdown=true
        DID_F195_Supplier_Ecu_SW_VerNum: assigned-ports=role-based-port-assignment={port-prototype=NvMService_AC3_SRBS_DID_F195_Supplier_Ecu_SW_VerNum, role=NvMService_AC3_SRBS}
          assigned-datas:
            role=ramBlock, used-data-element=DID_F195_Supplier_Ecu_SW_VerNum_MirrorBlock
            role=defaultValue, used-parameter-element=DID_F195_Supplier_Ecu_SW_VerNum_DefaultValue
          service-needs:
            nv block needs DID_F195_Supplier_Ecu_SW_VerNum: n-data-sets=1, ram-block-status-control=API, reliability=NO-PROTECTION, restore-at-start=true
        DID_F194_Supplier_Ecu_SW_PartNum: assigned-ports=role-based-port-assignment={port-prototype=NvMService_AC3_SRBS_DID_F194_Supplier_Ecu_SW_PartNum, role=NvMService_AC3_SRBS}
          assigned-datas:
            role=ramBlock, used-data-element=DID_F194_Supplier_Ecu_SW_PartNum_MirrorBlock
            role=defaultValue, used-parameter-element=DID_F194_Supplier_Ecu_SW_PartNum_DefaultValue
          service-needs:
            nv block needs DID_F194_Supplier_Ecu_SW_PartNum: n-data-sets=1, ram-block-status-control=API, reliability=NO-PROTECTION, restore-at-start=true, store-at-shutdown=false
        DID_F18B_FCA_ESLM_ECU_SW_App_Num: assigned-ports=role-based-port-assignment={port-prototype=NvMService_AC3_SRBS_DID_F18B_FCA_ESLM_ECU_SW_App_Num, role=NvMService_AC3_SRBS}
          assigned-datas:
            role=ramBlock, used-data-element=DID_F18B_FCA_ESLM_ECU_SW_App_Num_MirrorBlock
            role=defaultValue, used-parameter-element=DID_F18B_FCA_ESLM_ECU_SW_App_Num_DefaultValue
          service-needs:
            nv block needs DID_F18B_FCA_ESLM_ECU_SW_App_Num: n-data-sets=1, ram-block-status-control=API, reliability=NO-PROTECTION, restore-at-start=true, store-at-shutdown=false
        DID_F18A_FCA_ESLM_Ecu_SW_Cal_Num: assigned-ports=role-based-port-assignment={port-prototype=NvMService_AC3_SRBS_DID_F18A_FCA_ESLM_Ecu_SW_Cal_Num, role=NvMService_AC3_SRBS}
          assigned-datas:
            role=ramBlock, used-data-element=DID_F18A_FCA_ESLM_Ecu_SW_Cal_Num_MirrorBlock
            role=defaultValue, used-parameter-element=DID_F18A_FCA_ESLM_Ecu_SW_Cal_Num_DefaultValue
          service-needs:
            nv block needs DID_F18A_FCA_ESLM_Ecu_SW_Cal_Num: n-data-sets=1, ram-block-status-control=API, reliability=NO-PROTECTION, restore-at-start=true
        DID_F188_FCA_ESLM_Ecu_SW_Num: assigned-ports=role-based-port-assignment={port-prototype=NvMService_AC3_SRBS_DID_F188_FCA_ESLM_Ecu_SW_Num, role=NvMService_AC3_SRBS}
          assigned-datas:
            role=ramBlock, used-data-element=DID_F188_FCA_ESLM_Ecu_SW_Num_MirrorBlock
            role=defaultValue, used-parameter-element=DID_F188_FCA_ESLM_Ecu_SW_Num_DefaultValue
          service-needs:
            nv block needs DID_F188_FCA_ESLM_Ecu_SW_Num: n-data-sets=1, ram-block-status-control=API, reliability=NO-PROTECTION, restore-at-start=true, store-at-shutdown=false
        DID_F187_CODEP_Ecu_PartNum: assigned-ports=role-based-port-assignment={port-prototype=NvMService_AC3_SRBS_DID_F187_CODEP_Ecu_PartNum, role=NvMService_AC3_SRBS}
          assigned-datas:
            role=ramBlock, used-data-element=DID_F187_CODEP_Ecu_PartNum_MirrorBlock
            role=defaultValue, used-parameter-element=DID_F187_CODEP_Ecu_PartNum_DefaultValue
          service-needs:
            nv block needs DID_F187_CODEP_Ecu_PartNum: n-data-sets=1, ram-block-status-control=API, reliability=NO-PROTECTION, restore-at-start=true
        DID_F180_Boot_SW_Ver_Info: assigned-ports=role-based-port-assignment={port-prototype=NvMService_AC3_SRBS_DID_F180_Boot_SW_Ver_Info, role=NvMService_AC3_SRBS}
          assigned-datas:
            role=ramBlock, used-data-element=DID_F180_Boot_SW_Ver_Info_MirrorBlock
            role=defaultValue, used-parameter-element=DID_F180_Boot_SW_Ver_Info_DefaultValue
          service-needs:
            nv block needs DID_F180_Boot_SW_Ver_Info: n-data-sets=1, ram-block-status-control=API, reliability=NO-PROTECTION, restore-at-start=true, store-at-shutdown=false
        DID_F134_CODEP_Asm_PartNum: assigned-ports=role-based-port-assignment={port-prototype=NvMService_AC3_SRBS_DID_F134_CODEP_Asm_PartNum, role=NvMService_AC3_SRBS}
          assigned-datas:
            role=ramBlock, used-data-element=DID_F134_CODEP_Asm_PartNum_MirrorBlock
            role=defaultValue, used-parameter-element=DID_F134_CODEP_Asm_PartNum_DefaultValue
          service-needs:
            nv block needs DID_F134_CODEP_Asm_PartNum: n-data-sets=1, ram-block-status-control=API, reliability=NO-PROTECTION, restore-at-start=true, store-at-shutdown=false
        DID_F133_EBOM_Asm_PartNum: assigned-ports=role-based-port-assignment={port-prototype=NvMService_AC3_SRBS_DID_F133_EBOM_Asm_PartNum, role=NvMService_AC3_SRBS}
          assigned-datas:
            role=ramBlock, used-data-element=DID_F133_EBOM_Asm_PartNum_MirrorBlock
            role=defaultValue, used-parameter-element=DID_F133_EBOM_Asm_PartNum_DefaultValue
          service-needs:
            nv block needs DID_F133_EBOM_Asm_PartNum: n-data-sets=1, ram-block-status-control=API, reliability=NO-PROTECTION, restore-at-start=true, store-at-shutdown=false
        DID_F132_EBOM_Ecu_PartNum: assigned-ports=role-based-port-assignment={port-prototype=NvMService_AC3_SRBS_DID_F132_EBOM_Ecu_PartNum, role=NvMService_AC3_SRBS}
          assigned-datas:
            role=ramBlock, used-data-element=DID_F132_EBOM_Ecu_PartNum_MirrorBlock
            role=defaultValue, used-parameter-element=DID_F132_EBOM_Ecu_PartNum_DefaultValue
          service-needs:
            nv block needs DID_F132_EBOM_Ecu_PartNum: n-data-sets=1, ram-block-status-control=API, reliability=NO-PROTECTION, restore-at-start=true, store-at-shutdown=false
        DID_F110_Ecu_Diag_Info: assigned-ports=role-based-port-assignment={port-prototype=NvMService_AC3_SRBS_DID_F110_Ecu_Diag_Info, role=NvMService_AC3_SRBS}
          assigned-datas:
            role=ramBlock, used-data-element=DID_F110_Ecu_Diag_Info_MirrorBlock
            role=defaultValue, used-parameter-element=DID_F110_Ecu_Diag_Info_DefaultValue
          service-needs:
            nv block needs DID_F110_Ecu_Diag_Info: n-data-sets=1, ram-block-status-control=API, reliability=NO-PROTECTION, restore-at-start=true, store-at-shutdown=false
        UssSensorMarrData: assigned-ports=role-based-port-assignment={port-prototype=NvMService_AC3_SRBS_UssSensorMarrData, role=NvMService_AC3_SRBS}
          assigned-datas:
            role=ramBlock, used-data-element=UssSensorMarrData_MirrorBlock
            role=defaultValue, used-parameter-element=UssSensorMarrData_DefaultValue
          service-needs:
            nv block needs UssSensorMarrData: n-data-sets=1, ram-block-status-control=API, reliability=NO-PROTECTION, restore-at-start=true, store-at-shutdown=true
  swc implementation SWC_PartNumMgr_Implementation: programming-language=C, vendor-id=0, behavior=SWC_PartNumMgr_InternalBehavior
    code-descriptors:
      code Default: artifact-descriptors=autosar-engineering-object=category=SWSRC
